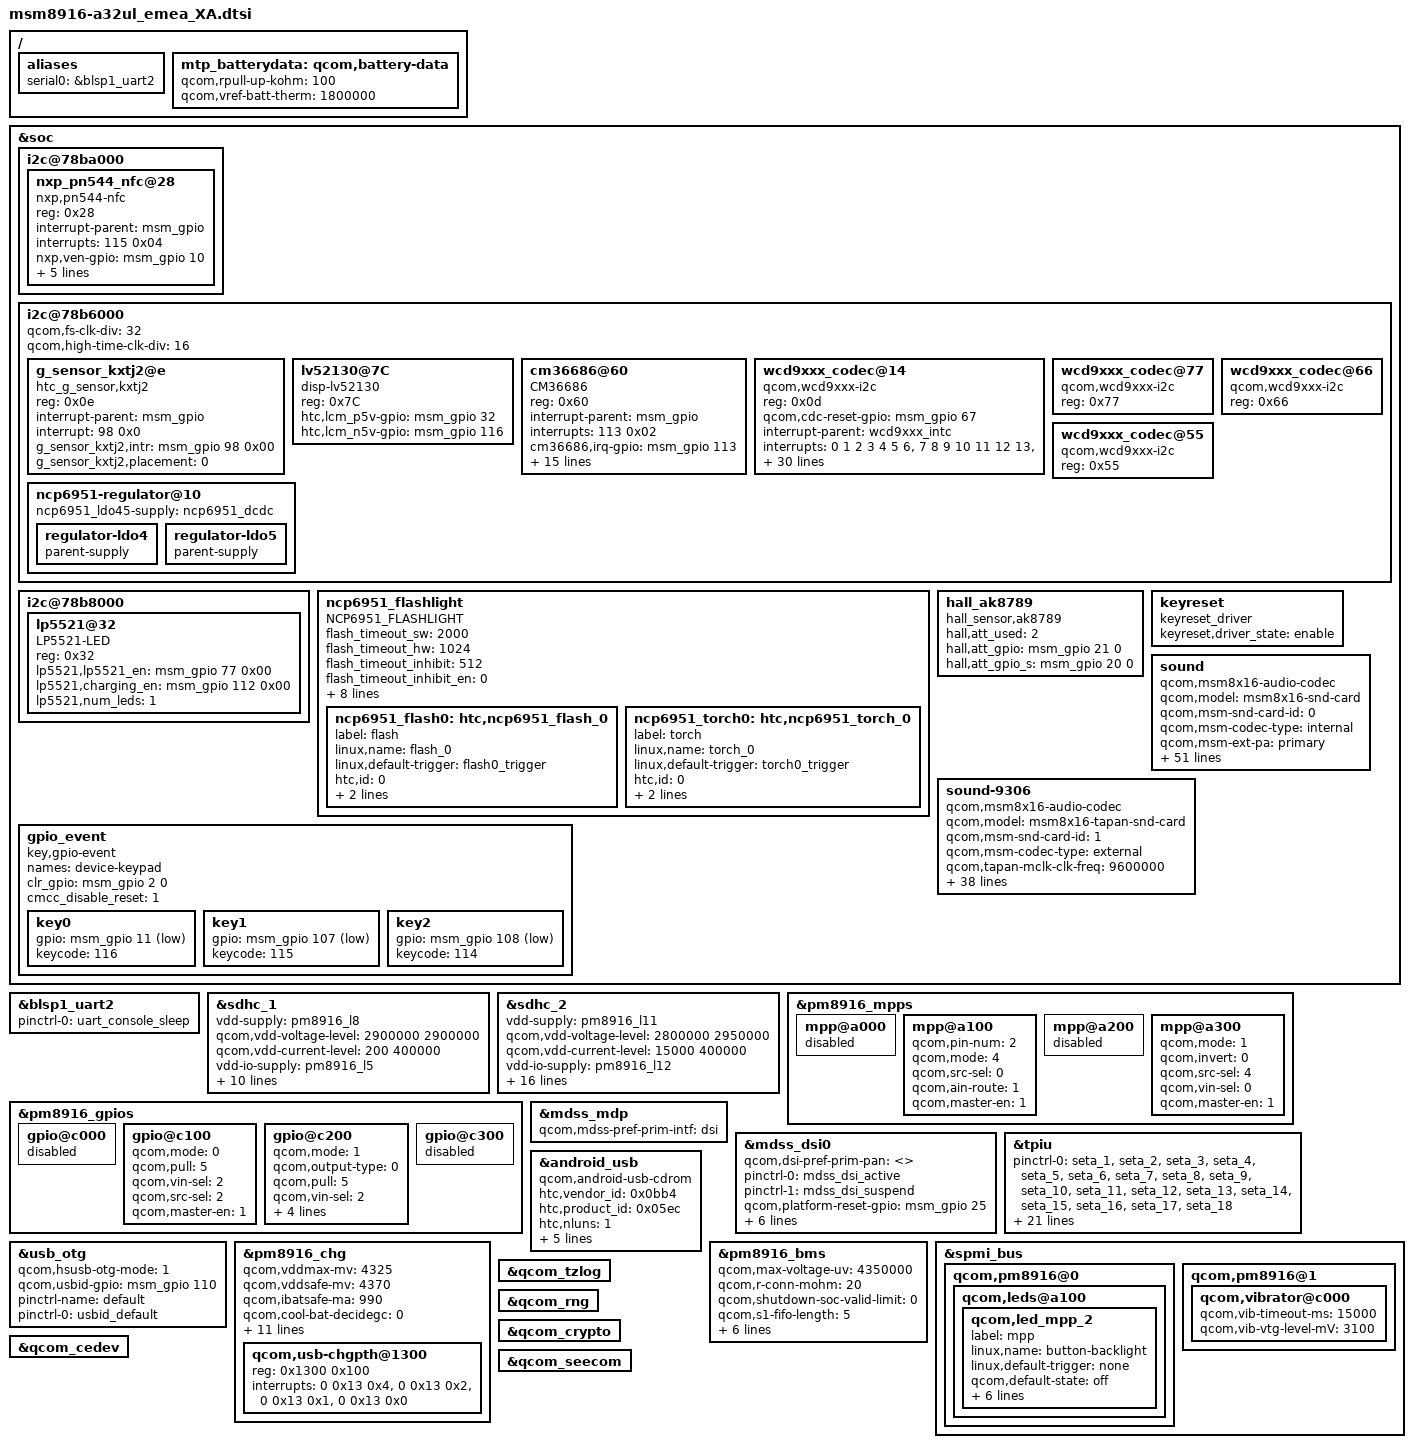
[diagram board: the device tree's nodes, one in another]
/* Copyright (c) 2014, The Linux Foundation. All rights reserved.
 *
 * This program is free software; you can redistribute it and/or modify
 * it under the terms of the GNU General Public License version 2 and
 * only version 2 as published by the Free Software Foundation.
 *
 * This program is distributed in the hope that it will be useful,
 * but WITHOUT ANY WARRANTY; without even the implied warranty of
 * MERCHANTABILITY or FITNESS FOR A PARTICULAR PURPOSE.  See the
 * GNU General Public License for more details.
 */

#include "msm8916.dtsi"
#include "msm8916-pinctrl-a32.dtsi"
#include "msm8916-camera-sensor-a32.dtsi"
#include "msm8916-touch-a32-config.dtsi"
#include "msm8916-ncp6951-regulator.dtsi"
#include "dsi-panel-a32.dtsi"

/ {
	aliases {
		serial0 = &blsp1_uart2;
	};
};

&soc {
	i2c@78ba000 { /* BLSP1 QUP6 */
                nxp_pn544_nfc@28 {  /* No NFC chip by default but Design Reserved */
                       compatible = "nxp,pn544-nfc";
                       reg = <0x28>;
                       interrupt-parent = <&msm_gpio>;
                       interrupts = <115 0x04>;
                       nxp,ven-gpio = <&msm_gpio 10 0x00>;
                       nxp,pvdd-gpio = <&msm_gpio 121 0x00>;
                       nxp,irq-gpio = <&msm_gpio 115 0x00>;
                       nxp,fwdl-gpio = <&msm_gpio 49 0x00>;
                       nxp,ven_isinvert = <0>;
                       nxp,isalive = <1>; /* hboot will not update it for A32 */
                };

	};

	i2c@78b6000 { /* BLSP1 QUP2 */
		qcom,fs-clk-div = <32>;
		qcom,high-time-clk-div = <16>;

		g_sensor_kxtj2@e {
			compatible = "htc_g_sensor,kxtj2";
			reg = <0x0e>;
			interrupt-parent = <&msm_gpio>;
			interrupt = <98 0x0>;
			g_sensor_kxtj2,intr = <&msm_gpio 98 0x00>;
			g_sensor_kxtj2,placement = <0>;
                };

		lv52130@7C {
			compatible = "disp-lv52130";
			reg = <0x7C>;
			htc,lcm_p5v-gpio = <&msm_gpio 32 0>;
			htc,lcm_n5v-gpio = <&msm_gpio 116 0>;
		};

		cm36686@60 {
                        compatible = "CM36686";
                        reg = <0x60>;
                        interrupt-parent = <&msm_gpio>;
                        interrupts = <113 0x02>;
                        interrupt-names = "cm36686";
                        cm36686,irq-gpio = <&msm_gpio 113 0x00>;
                        cm36686,levels = <9 27 45 189 449 2829 4249 7729 10269 65535>;
                        cm36686,golden_adc = <0x08d2>;
                        cm36686,cm36686_slave_address = <0x60>;
			cm36686,ps_th_add = <15>;
                        cm36686,ps1_thd_set = <0x15>;
                        cm36686,ps1_thd_no_cal = <0x5f>;
                        cm36686,dynamical_threshold = <1>;
                        cm36686,dark_level = <3>;
                        cm36686,ps_duty = <0>;
                        cm36686,ps_pers = <1>;
                        cm36686,ps_it = <7>;
                        cm36686,ps_hd = <0>;
                        cm36686,ps_led_current = <2>;
			SR_2v85-supply = <&pm8916_l17>;
		};

		wcd9xxx_codec@14 {
			compatible = "qcom,wcd9xxx-i2c";
			reg = <0x0d>;
			qcom,cdc-reset-gpio = <&msm_gpio 67 0>;
			interrupt-parent = <&wcd9xxx_intc>;
			interrupts = <0 1 2 3 4 5 6>, <7 8 9 10 11 12 13>,
					<14 15 16 17 18 19 20>, <21 22 23 24 25 26 27 28>;

			cdc-vdd-buck-supply = <&pm8916_s4>;
			qcom,cdc-vdd-buck-voltage = <1800000 2150000>;
			qcom,cdc-vdd-buck-current = <650000>;

			cdc-vdd-h-supply = <&pm8916_l15>;
			qcom,cdc-vdd-h-voltage = <1800000 1800000>;
			qcom,cdc-vdd-h-current = <25000>;

			cdc-vdd-px-supply = <&pm8916_l6>;
			qcom,cdc-vdd-px-voltage = <1800000 1800000>;
			qcom,cdc-vdd-px-current = <25000>;

			cdc-vdd-cx-supply = <&pm8916_l2>;
			qcom,cdc-vdd-cx-voltage = <1200000 1200000>;
			qcom,cdc-vdd-cx-current = <2000>;

			cdc-vdd-buckhelper-supply = <&pm8916_l15>;
			qcom,cdc-vdd-buckhelper-voltage = <1775000 2125000>;
			qcom,cdc-vdd-buckhelper-current = <10000>;

			qcom,cdc-static-supplies = "cdc-vdd-h",
						   "cdc-vdd-px",
						   "cdc-vdd-cx";

			qcom,cdc-cp-supplies = "cdc-vdd-buck",
						"cdc-vdd-buckhelper";

			qcom,cdc-micbias-ldoh-v = <0x3>;
			qcom,cdc-micbias-cfilt1-mv = <1800>;
			qcom,cdc-micbias-cfilt2-mv = <2700>;
			qcom,cdc-micbias-cfilt3-mv = <1800>;

			qcom,cdc-micbias1-cfilt-sel = <0x0>;
			qcom,cdc-micbias2-cfilt-sel = <0x1>;
			qcom,cdc-micbias3-cfilt-sel = <0x2>;

			qcom,cdc-mclk-clk-rate = <9600000>;
		};

		wcd9xxx_codec@77 {
			compatible = "qcom,wcd9xxx-i2c";
			reg = <0x77>;
		};

		wcd9xxx_codec@66 {
			compatible = "qcom,wcd9xxx-i2c";
			reg = <0x66>;
		};

		wcd9xxx_codec@55 {
			compatible = "qcom,wcd9xxx-i2c";
			reg = <0x55>;
		};

		ncp6951-regulator@10 {
			ncp6951_ldo45-supply = <&ncp6951_dcdc>;
			regulator-ldo4 {
				parent-supply;
			};
			regulator-ldo5 {
				parent-supply;
			};
		};
	};

	i2c@78b8000 {
		lp5521@32 {
			compatible = "LP5521-LED";
			reg = <0x32>;
			lp5521,lp5521_en = <&msm_gpio 77 0x00>;
			lp5521,charging_en = <&msm_gpio 112 0x00>;
			lp5521,num_leds = <1>;
		};
	};

	ncp6951_flashlight {
		compatible = "NCP6951_FLASHLIGHT";

		flash_timeout_sw	= <2000>;
		flash_timeout_hw	= <1024>;
		flash_timeout_inhibit	= <512>;
		flash_timeout_inhibit_en= <0>;
		flash_timeout_red_eye_en= <0>;

		flash_current_max	= <1000>;
		flash_current_reduced	= <200>;
		flash_current_red_eye	= <200>;
		torch_current_max	= <200>;

		flash_count_red_eye	= <1>;

		ncp6951_pin_flen	= <&msm_gpio 17 0>;
		ncp6951_pin_flsel	= <&msm_gpio 109 0>;

		ncp6951_flash0: htc,ncp6951_flash_0 {
			label = "flash";
			linux,name = "flash_0";
			linux,default-trigger = "flash0_trigger";
			htc,id = <0>;
			htc,default-state = "off";
			htc,max-current = <1000>;
		};

		ncp6951_torch0: htc,ncp6951_torch_0 {
			label = "torch";
			linux,name = "torch_0";
			linux,default-trigger = "torch0_trigger";
			htc,id = <0>;
			htc,default-state = "off";
			htc,max-current = <200>;
		};
	};

	hall_ak8789 {
		compatible = "hall_sensor,ak8789";
		hall,att_used = <2>;
		hall,att_gpio = <&msm_gpio 21 0>;
		hall,att_gpio_s = <&msm_gpio 20 0>;
	};

	gpio_event {
	compatible = "key,gpio-event";
	names = "device-keypad";
	clr_gpio = <&msm_gpio 2 0>;
	cmcc_disable_reset = <1>;

		key0 {
			gpio    = <&msm_gpio 11 3>;
			keycode = <116>;	//pwr
			//pull = <1>;		//0=pull up, 1=no pull
		};
		key1 {
			gpio    = <&msm_gpio 107 3>;
			keycode = <115>;	//vUP
		};
		key2 {
			gpio    = <&msm_gpio 108 3>;
			keycode = <114>;	//vDN
		};
	};

	keyreset {
		compatible = "keyreset_driver";
		keyreset,driver_state = "enable";
	};

	sound {
		compatible = "qcom,msm8x16-audio-codec";
		qcom,model = "msm8x16-snd-card";
		qcom,msm-snd-card-id = <0>;
		qcom,msm-codec-type = "internal";
		qcom,msm-ext-pa = "primary";
		qcom,msm-mbhc-hphl-swh = <1>;
		qcom,msm-mbhc-gnd-swh = <1>;
		qcom,msm-mclk-freq = <9600000>;
		qcom,msm-hs-micbias-type = "internal";
		qcom,audio-routing =
			"RX_BIAS", "MCLK",
			"SPK_RX_BIAS", "MCLK",
			"INT_LDO_H", "MCLK",
			"MIC BIAS Internal1", "Handset Mic",
			"MIC BIAS Internal2", "Headset Mic",
			"MIC BIAS Internal3", "Secondary Mic",
			"AMIC1", "MIC BIAS Internal1",
			"AMIC2", "MIC BIAS Internal2",
			"AMIC3", "MIC BIAS Internal3";
		pinctrl-names = "cdc_lines_act",
				"cdc_lines_sus",
				"cross_conn_det_act",
				"cross_conn_det_sus";
		pinctrl-0 = <&cdc_pdm_lines_act>;
		pinctrl-1 = <&cdc_pdm_lines_sus>;
		pinctrl-2 = <&cdc_pdm_lines_act &cdc_ext_pa_act
						&cdc_ext_pa_ws_act>;
		pinctrl-3 = <&cdc_pdm_lines_sus &cdc_ext_pa_sus
						&cdc_ext_pa_ws_sus>;
		asoc-platform = <&pcm0>, <&pcm1>, <&voip>, <&voice>,
				<&loopback>, <&compress>, <&hostless>,
				<&afe>, <&lsm>, <&routing>, <&lpa>;
		asoc-platform-names = "msm-pcm-dsp.0", "msm-pcm-dsp.1",
				"msm-voip-dsp", "msm-pcm-voice", "msm-pcm-loopback",
				"msm-compress-dsp", "msm-pcm-hostless", "msm-pcm-afe",
				"msm-lsm-client", "msm-pcm-routing", "msm-pcm-lpa";
		asoc-cpu = <&dai_pri_auxpcm>, <&dai_hdmi>,
				<&dai_mi2s0>, <&dai_mi2s1>, <&dai_mi2s2>, <&dai_mi2s3>,
				<&sb_0_rx>, <&sb_0_tx>, <&sb_1_rx>, <&sb_1_tx>,
				<&sb_3_rx>, <&sb_3_tx>, <&sb_4_rx>, <&sb_4_tx>,
				<&bt_sco_rx>, <&bt_sco_tx>, <&int_fm_rx>, <&int_fm_tx>,
				<&afe_pcm_rx>, <&afe_pcm_tx>, <&afe_proxy_rx>, <&afe_proxy_tx>,
				<&incall_record_rx>, <&incall_record_tx>, <&incall_music_rx>,
				<&incall_music_2_rx>;
		asoc-cpu-names = "msm-dai-q6-auxpcm.1", "msm-dai-q6-hdmi.8",
				"msm-dai-q6-mi2s.0", "msm-dai-q6-mi2s.1",
				"msm-dai-q6-mi2s.2", "msm-dai-q6-mi2s.3",
				"msm-dai-q6-dev.16384", "msm-dai-q6-dev.16385",
				"msm-dai-q6-dev.16386", "msm-dai-q6-dev.16387",
				"msm-dai-q6-dev.16390", "msm-dai-q6-dev.16391",
				"msm-dai-q6-dev.16392", "msm-dai-q6-dev.16393",
				"msm-dai-q6-dev.12288", "msm-dai-q6-dev.12289",
				"msm-dai-q6-dev.12292", "msm-dai-q6-dev.12293",
				"msm-dai-q6-dev.224", "msm-dai-q6-dev.225",
				"msm-dai-q6-dev.241", "msm-dai-q6-dev.240",
				"msm-dai-q6-dev.32771", "msm-dai-q6-dev.32772",
				"msm-dai-q6-dev.32773", "msm-dai-q6-dev.32770";
		asoc-codec = <&stub_codec>, <&pm8916_tombak_dig>;
		asoc-codec-names = "msm-stub-codec.1", "tombak_codec";
	};

	sound-9306 {
		compatible = "qcom,msm8x16-audio-codec";
		qcom,model = "msm8x16-tapan-snd-card";
		qcom,msm-snd-card-id = <1>;
		qcom,msm-codec-type = "external";
		qcom,tapan-mclk-clk-freq = <9600000>;
		qcom,prim-auxpcm-gpio-clk  = <&msm_gpio 63 0>;
		qcom,prim-auxpcm-gpio-sync = <&msm_gpio 64 0>;
		qcom,prim-auxpcm-gpio-din  = <&msm_gpio 65 0>;
		qcom,prim-auxpcm-gpio-dout = <&msm_gpio 66 0>;
		qcom,prim-auxpcm-gpio-set = "prim-gpio-prim";
		qcom,tapan-codec-9302;
		pinctrl-names = "ext_cdc_tlmm_lines_act",
				"ext_cdc_tlmm_lines_sus";
		pinctrl-0 = <&ext_cdc_tlmm_lines_act>;
		pinctrl-1 = <&ext_cdc_tlmm_lines_sus>;
		qcom,audio-routing =
			"RX_BIAS", "MCLK",
			"LDO_H", "MCLK",
			"SPK_OUT", "MCLK",
			"SPK_OUT", "EXT_VDD_SPKR",
			"AMIC1", "MIC BIAS1 Internal1",
			"MIC BIAS1 Internal1", "Handset Mic",
			"AMIC2", "MIC BIAS2 External",
			"MIC BIAS2 External", "Headset Mic",
			"AMIC4", "MIC BIAS2 External",
			"MIC BIAS2 External", "ANCRight Headset Mic",
			"AMIC5", "MIC BIAS2 External",
			"MIC BIAS2 External", "ANCLeft Headset Mic",
			"DMIC1", "MIC BIAS1 External",
			"MIC BIAS1 External", "Digital Mic1",
			"DMIC2", "MIC BIAS1 External",
			"MIC BIAS1 External", "Digital Mic2",
			"DMIC3", "MIC BIAS3 External",
			"MIC BIAS3 External", "Digital Mic3",
			"DMIC4", "MIC BIAS3 External",
			"MIC BIAS3 External", "Digital Mic4";
		asoc-platform = <&pcm0>, <&pcm1>, <&voip>, <&voice>,
				<&loopback>, <&compress>, <&hostless>,
				<&afe>, <&lsm>, <&routing>;
		asoc-platform-names = "msm-pcm-dsp.0", "msm-pcm-dsp.1", "msm-pcm-dsp.2",
				"msm-voip-dsp", "msm-pcm-voice", "msm-pcm-loopback",
				"msm-compress-dsp", "msm-pcm-hostless", "msm-pcm-afe",
				"msm-lsm-client", "msm-pcm-routing";
		asoc-cpu = <&dai_pri_auxpcm>, <&dai_hdmi>,
				<&dai_mi2s0>, <&dai_mi2s1>, <&dai_mi2s2>, <&dai_mi2s3>;
		asoc-cpu-names = "msm-dai-q6-auxpcm.1", "msm-dai-q6-hdmi.8",
				"msm-dai-q6-mi2s.0", "msm-dai-q6-mi2s.1",
				"msm-dai-q6-mi2s.2", "msm-dai-q6-mi2s.3";
	};
};

&blsp1_uart2 {
	status = "ok";
	pinctrl-names = "default";
	pinctrl-0 = <&uart_console_sleep>;
};

&sdhc_1 {
	vdd-supply = <&pm8916_l8>;
	qcom,vdd-voltage-level = <2900000 2900000>;
	qcom,vdd-current-level = <200 400000>;

	vdd-io-supply = <&pm8916_l5>;
	qcom,vdd-io-always-on;
	qcom,vdd-io-lpm-sup;
	qcom,vdd-io-voltage-level = <1800000 1800000>;
	qcom,vdd-io-current-level = <200 60000>;

	pinctrl-names = "active", "sleep";
	pinctrl-0 = <&sdc1_clk_on &sdc1_cmd_on &sdc1_data_on>;
	pinctrl-1 = <&sdc1_clk_off &sdc1_cmd_off &sdc1_data_off>;
        htc,slot-type = <0>;

	qcom,nonremovable;

	status = "ok";
};

&sdhc_2 {
	vdd-supply = <&pm8916_l11>;
	qcom,vdd-voltage-level = <2800000 2950000>;
	qcom,vdd-current-level = <15000 400000>;

	vdd-io-supply = <&pm8916_l12>;
	qcom,vdd-io-voltage-level = <1800000 2950000>;
	qcom,vdd-io-current-level = <200 50000>;

	pinctrl-names = "active", "sleep";
	pinctrl-0 = <&sdc2_clk_on &sdc2_cmd_on &sdc2_data_on &sdc2_cd_on>;
	pinctrl-1 = <&sdc2_clk_on_ddr50_sdr104 &sdc2_cmd_on_ddr50_sdr104 &sdc2_data_on_ddr50_sdr104 &sdc2_cd_on>;
	pinctrl-2 = <&sdc2_clk_off &sdc2_cmd_off &sdc2_data_off &sdc2_cd_off>;

	#address-cells = <0>;
	interrupt-parent = <&sdhc_2>;
	interrupts = <0 1 2>;
	#interrupt-cells = <1>;
	interrupt-map-mask = <0xffffffff>;
	interrupt-map = <0 &intc 0 125 0
			1 &intc 0 221 0
			2 &msm_gpio 38 0>;
	interrupt-names = "hc_irq", "pwr_irq", "status_irq";
	cd-gpios = <&msm_gpio 38 0x1>;
        htc,slot-type = <1>;

	status = "ok";
};

&pm8916_mpps {
	mpp@a000 { /* MPP 1 */
		/* VDD_PX */
		status = "disabled";
	};

	mpp@a100 { /* MPP 2 */
		/* ++ 2014/07/08, USB team, PCN00030 ++ */
		/* USB_HS_ID */
		qcom,pin-num   = <2>;
		qcom,mode      = <4>;   //QPNP_PIN_MODE_AIN
		qcom,src-sel   = <0>;   //QPNP_PIN_SEL_FUNC_CONSTANT
		qcom,ain-route = <1>;   //QPNP_PIN_AIN_AMUX_CH8
		qcom,master-en = <1>;   //ENABLE FEATURE
		/* -- 2014/07/08, USB team, PCN00030 -- */
	};

	mpp@a200 { /* MPP 3 */
		/* VREF DAC */
		status = "disabled";
	};

	mpp@a300 { /* MPP 4 */
		/* Backlight PWM */
		qcom,mode = <1>;		/* Digital output */
		qcom,invert = <0>;		/* Disable invert */
		qcom,src-sel = <4>;		/* DTEST1 */
		qcom,vin-sel = <0>;		/* VPH_PWR */
		qcom,master-en = <1>;		/* Enable MPP */
	};
};

&pm8916_gpios {
	gpio@c000 { /* GPIO 1 */
		/* Battery UICC Alarm */
		status = "disabled";
	};

	gpio@c100 { /* GPIO 2 */
		/* NFC_CLK_REQ */
		qcom,mode = <0>; /* QPNP_PIN_MODE_DIG_IN */
		qcom,pull = <5>; /* QPNP_PIN_PULL_NO */
		qcom,vin-sel = <2>; /* QPNP_PIN_VIN2 */
		qcom,src-sel = <2>; /* QPNP_PIN_SEL_FUNC_1 */
		qcom,master-en = <1>;
	};

	gpio@c200 { /* GPIO 3 */
		qcom,mode = <1>;                /* QPNP_PIN_MODE_DIG_OUT */
		qcom,output-type = <0>;         /* QPNP_PIN_OUT_BUF_CMOS */
		qcom,pull = <5>;                /* QPNP_PIN_PULL_NO */
		qcom,vin-sel = <2>;             /* QPNP_PIN_VIN2  */
		qcom,out-strength = <1>;        /* QPNP_PIN_OUT_STRENGTH_LOW */
		qcom,src-sel = <0>;             /* QPNP_PIN_SEL_FUNC_CONSTANT */
		qcom,master-en = <1>;
		qcom,invert = <1>;
	};

	gpio@c300 { /* GPIO 4 */
		/* External regulator control for APC */
		status = "disabled";
	};
};
/*
#include "dsi-panel-jdi-1080p-video.dtsi"
#include "dsi-panel-nt35590-720p-video.dtsi"
#include "dsi-panel-nt35590-720p-cmd.dtsi"
#include "dsi-panel-hx8394d-720p-video.dtsi"
*/
&mdss_mdp {
	qcom,mdss-pref-prim-intf = "dsi";
};
/*
&dsi_jdi_1080_vid {
	qcom,mdss-dsi-bl-pmic-control-type = "bl_ctrl_pwm";
	qcom,mdss-dsi-bl-pmic-pwm-frequency = <100>;
	qcom,mdss-dsi-bl-pmic-bank-select = <0>;
	qcom,mdss-dsi-pwm-gpio = <&pm8916_mpps 4 0>;
	qcom,cont-splash-enabled;
};

&dsi_nt35590_720_vid {
	qcom,mdss-dsi-bl-pmic-control-type = "bl_ctrl_pwm";
	qcom,mdss-dsi-bl-pmic-pwm-frequency = <100>;
	qcom,mdss-dsi-bl-pmic-bank-select = <0>;
	qcom,mdss-dsi-pwm-gpio = <&pm8916_mpps 4 0>;
	qcom,cont-splash-enabled;
	qcom,esd-check-enabled;
};

&dsi_nt35590_720_cmd {
	qcom,mdss-dsi-bl-pmic-control-type = "bl_ctrl_pwm";
	qcom,mdss-dsi-bl-pmic-pwm-frequency = <100>;
	qcom,mdss-dsi-bl-pmic-bank-select = <0>;
	qcom,mdss-dsi-pwm-gpio = <&pm8916_mpps 4 0>;
	qcom,cont-splash-enabled;
	qcom,esd-check-enabled;
};

&dsi_hx8394d_720_vid {
	qcom,mdss-dsi-bl-pmic-control-type = "bl_ctrl_pwm";
	qcom,mdss-dsi-bl-pmic-pwm-frequency = <100>;
	qcom,mdss-dsi-bl-pmic-bank-select = <0>;
	qcom,mdss-dsi-pwm-gpio = <&pm8916_mpps 4 0>;
	qcom,cont-splash-enabled;
};

&pmx_mdss {
	qcom,num-grp-pins = <3>;
	qcom,pins = <&gp 97>, <&gp 25>, <&gp 98>;
};

&pmx_mdss_te {
	qcom,num-grp-pins = <1>;
	qcom,pins = <&gp 24>;
};
*/
&mdss_dsi0 {
	qcom,dsi-pref-prim-pan = <>;
	pinctrl-names = "mdss_default", "mdss_sleep";
	pinctrl-0 = <&mdss_dsi_active>;
	pinctrl-1 = <&mdss_dsi_suspend>;

	qcom,platform-reset-gpio = <&msm_gpio 25 0>;
	htc,lcm_p5v-gpio = <&msm_gpio 32 0>;
	htc,lcm_n5v-gpio = <&msm_gpio 116 0>;
	htc,lcm_ld0_1v8_en-gpio = <&msm_gpio 120 0>;
	qcom,regulator-ldo-mode;
	qcom,platform-regulator-settings = [02 09 03 00 20 00 01];
};

/* CoreSight */
&tpiu {
	pinctrl-names = "seta-pctrl", "setb-pctrl", "sdcard", "trace",
			"swduart", "swdtrc", "jtag", "spmi";
	/* Mictor */
	pinctrl-0 = <&seta_1 &seta_2 &seta_3 &seta_4 &seta_5 &seta_6 &seta_7
		     &seta_8 &seta_9 &seta_10 &seta_11 &seta_12 &seta_13
		     &seta_14 &seta_15 &seta_16 &seta_17 &seta_18>;
	pinctrl-1 = <&setb_1 &setb_2 &setb_3 &setb_4 &setb_5 &setb_6 &setb_7
		     &setb_8 &setb_9 &setb_10 &setb_11 &setb_12 &setb_13
		     &setb_14 &setb_15 &setb_16 &setb_17 &setb_18>;
	/* NIDnT */
	pinctrl-2 = <&qdsd_clk_sdcard &qdsd_cmd_sdcard
		    &qdsd_data0_sdcard &qdsd_data1_sdcard
		    &qdsd_data2_sdcard &qdsd_data3_sdcard>;
	pinctrl-3 = <&qdsd_clk_trace &qdsd_cmd_trace
		    &qdsd_data0_trace &qdsd_data1_trace
		    &qdsd_data2_trace &qdsd_data3_trace>;
	pinctrl-4 = <&qdsd_cmd_swduart &qdsd_data0_swduart
		    &qdsd_data1_swduart &qdsd_data2_swduart
		    &qdsd_data3_swduart>;
	pinctrl-5 = <&qdsd_clk_swdtrc &qdsd_cmd_swdtrc
		    &qdsd_data0_swdtrc &qdsd_data1_swdtrc
		    &qdsd_data2_swdtrc &qdsd_data3_swdtrc>;
	pinctrl-6 = <&qdsd_cmd_jtag &qdsd_data0_jtag
		    &qdsd_data1_jtag &qdsd_data2_jtag
		    &qdsd_data3_jtag>;
	pinctrl-7 = <&qdsd_clk_spmi &qdsd_cmd_spmi
		    &qdsd_data0_spmi &qdsd_data3_spmi>;
};

/* ++ 2014/08/05, USB team, PCN00034 ++ */
&usb_otg {
	qcom,hsusb-otg-mode = <1>;
	qcom,usbid-gpio = <&msm_gpio 110 0>;
	pinctrl-name = "default";
	pinctrl-0 = <&usbid_default>;
	/*vbus_otg-supply = <&smb1360_otg_supply>;*/
};

&android_usb {
	qcom,android-usb-cdrom;
	htc,vendor_id = /bits/ 16 <0x0bb4>;
	htc,product_id = /bits/ 16 <0x05ec>;
	htc,nluns = <1>;
	htc,cdrom_lun = <1>;
	htc,usb_rmnet_interface = "smd,bam";
	htc,usb_diag_interface = "diag";
	htc,fserial_init_string = "smd:modem,tty,tty:autobot,tty:serial,tty:autobot,tty:acm";
};
/* -- 2014/08/05, USB team, PCN00034 -- */

&pm8916_chg {
        qcom,vddmax-mv = <4325>;
        qcom,vddsafe-mv = <4370>;
        qcom,ibatsafe-ma = <990>;
        qcom,cool-bat-decidegc = <0>;
        qcom,warm-bat-decidegc = <480>;
        qcom,cool-bat-mv = <4325>;
        qcom,warm-bat-mv = <4000>;
        qcom,ibatmax-warm-ma = <990>;
        qcom,ibatmax-cool-ma = <990>;
        qcom,resume-soc = <95>;
        qcom,pmic-revid = <&pm8916_revid>;
        qcom,disable-vbatdet-based-recharge;
        qcom,ovp_gpio = <&msm_gpio 31 0>;
        qcom,tchg-mins = <960>;

        qcom,ibatterm-ma = <210>;
	status = "ok";

        qcom,usb-chgpth@1300 {
                reg = <0x1300 0x100>;
                interrupts =    <0 0x13 0x4>,
                                <0 0x13 0x2>,
                                <0 0x13 0x1>,
                                <0 0x13 0x0>;
                interrupt-names =       "usb-over-temp",
                                        "chg-gone",
                                        "usbin-valid",
                                        "coarse-det-usb";
        };
};

/ {
        mtp_batterydata: qcom,battery-data {
                qcom,rpull-up-kohm = <100>;
                qcom,vref-batt-therm = <1800000>;

                #include "batterydata-a32-8x16-id1.dtsi"
                #include "batterydata-a32-8x16-id2.dtsi"
        };
};

&pm8916_bms {
        qcom,max-voltage-uv = <4350000>;
        qcom,r-conn-mohm = <20>;
        qcom,shutdown-soc-valid-limit = <0>;
        qcom,s1-fifo-length = <5>;

        qcom,stored-batt-magic-num= <(-1)>;
        qcom,stored-batt-soc= <(-1)>;
        qcom,stored-batt-update-time= <(-1)>;
        qcom,store-batt-data-soc-thre = <100>;
        qcom,is-embeded-batt = <1>;
	status = "ok";
        qcom,battery-data = <&mtp_batterydata>;
};

&spmi_bus {
	qcom,pm8916@0 {
		qcom,leds@a100 {
			status = "okay";
			qcom,led_mpp_2 {
				label = "mpp";
				linux,name = "button-backlight";
				linux,default-trigger = "none";
				qcom,default-state = "off";
				qcom,max-current = <40>;
				qcom,current-setting = <5>;
				qcom,id = <6>;
				qcom,mode = "manual";
				qcom,source-sel = <1>;
				qcom,mode-ctrl = <0x60>;
			};
		};
	};
};

&qcom_tzlog {
	status = "okay";
};

&qcom_rng {
	status = "okay";
};

&qcom_crypto {
	status = "okay";
};

&qcom_cedev {
	status = "okay";
};

&qcom_seecom {
	status = "okay";
};

&spmi_bus {
	qcom,pm8916@1 {
		qcom,vibrator@c000 {
			status = "okay";
			qcom,vib-timeout-ms = <15000>;
			qcom,vib-vtg-level-mV = <3100>;
		};
	};
};
